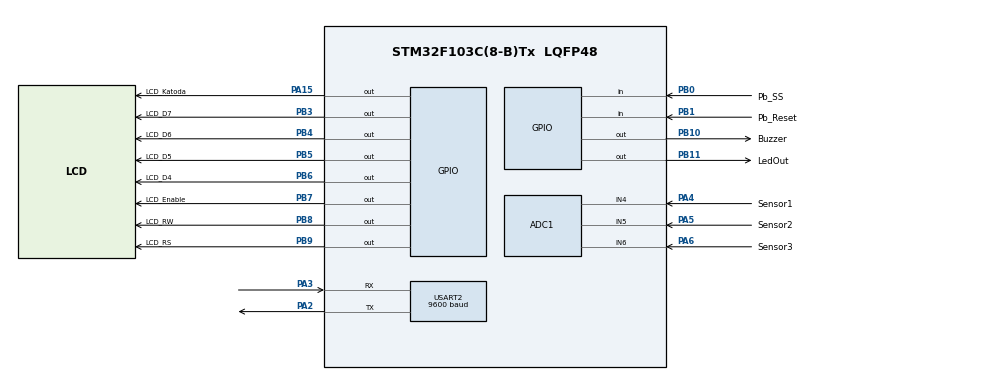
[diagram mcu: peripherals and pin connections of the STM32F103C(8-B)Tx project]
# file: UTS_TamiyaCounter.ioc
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ADC1.Channel-0\#ChannelRegularConversion=ADC_CHANNEL_4
ADC1.Channel-1\#ChannelRegularConversion=ADC_CHANNEL_5
ADC1.Channel-2\#ChannelRegularConversion=ADC_CHANNEL_6
ADC1.Channel-3\#ChannelRegularConversion=ADC_CHANNEL_4
ADC1.ContinuousConvMode=ENABLE
ADC1.NbrOfConversion=4
ADC1.NbrOfConversionFlag=1
ADC1.Rank-0\#ChannelRegularConversion=1
ADC1.Rank-1\#ChannelRegularConversion=2
ADC1.Rank-2\#ChannelRegularConversion=3
ADC1.Rank-3\#ChannelRegularConversion=4
ADC1.SamplingTime-0\#ChannelRegularConversion=ADC_SAMPLETIME_239CYCLES_5
ADC1.SamplingTime-1\#ChannelRegularConversion=ADC_SAMPLETIME_239CYCLES_5
ADC1.SamplingTime-2\#ChannelRegularConversion=ADC_SAMPLETIME_239CYCLES_5
ADC1.SamplingTime-3\#ChannelRegularConversion=ADC_SAMPLETIME_239CYCLES_5
ADC1.master=1
Dma.ADC1.0.Direction=DMA_PERIPH_TO_MEMORY
Dma.ADC1.0.Instance=DMA1_Channel1
Dma.ADC1.0.MemDataAlignment=DMA_MDATAALIGN_WORD
Dma.ADC1.0.MemInc=DMA_MINC_ENABLE
Dma.ADC1.0.Mode=DMA_CIRCULAR
Dma.ADC1.0.PeriphDataAlignment=DMA_PDATAALIGN_WORD
Dma.ADC1.0.PeriphInc=DMA_PINC_DISABLE
Dma.ADC1.0.Priority=DMA_PRIORITY_LOW
Dma.Request0=ADC1
Mcu.Family=STM32F1
Mcu.Name=STM32F103C(8-B)Tx
Mcu.Package=LQFP48
NVIC.ADC1_2_IRQn=true\:0\:0\:false\:false\:true\:true\:true
NVIC.DMA1_Channel1_IRQn=true\:0\:0\:false\:false\:true\:false\:true
NVIC.PriorityGroup=NVIC_PRIORITYGROUP_4
PA13.Mode=Serial_Wire
PA13.Signal=SYS_JTMS-SWDIO
PA14.Mode=Serial_Wire
PA14.Signal=SYS_JTCK-SWCLK
PA15.GPIO_Label=LCD_Katoda
PA15.Signal=GPIO_Output
PA2.Mode=Asynchronous
PA2.Signal=USART2_TX
PA3.Mode=Asynchronous
PA3.Signal=USART2_RX
PA4.GPIO_Label=Sensor1
PA4.Signal=ADCx_IN4
PA5.GPIO_Label=Sensor2
PA5.Signal=ADCx_IN5
PA6.GPIO_Label=Sensor3
PA6.Signal=ADCx_IN6
PB0.GPIO_Label=Pb_SS
PB0.GPIO_PuPd=GPIO_PULLUP
PB0.Signal=GPIO_Input
PB1.GPIO_Label=Pb_Reset
PB1.GPIO_PuPd=GPIO_PULLUP
PB1.Signal=GPIO_Input
PB10.GPIO_Label=Buzzer
PB10.Signal=GPIO_Output
PB11.GPIO_Label=LedOut
PB11.Signal=GPIO_Output
PB3.GPIO_Label=LCD_D7
PB3.Signal=GPIO_Output
PB4.GPIO_Label=LCD_D6
PB4.Signal=GPIO_Output
PB5.GPIO_Label=LCD_D5
PB5.Signal=GPIO_Output
PB6.GPIO_Label=LCD_D4
PB6.Signal=GPIO_Output
PB7.GPIO_Label=LCD_Enable
PB7.Signal=GPIO_Output
PB8.GPIO_Label=LCD_RW
PB8.Signal=GPIO_Output
PB9.GPIO_Label=LCD_RS
PB9.Signal=GPIO_Output
PD0-OSC_IN.Mode=HSE-External-Oscillator
PD0-OSC_IN.Signal=RCC_OSC_IN
PD1-OSC_OUT.Mode=HSE-External-Oscillator
PD1-OSC_OUT.Signal=RCC_OSC_OUT
ProjectManager.HeapSize=0x200
ProjectManager.StackSize=0x400
ProjectManager.TargetToolchain=STM32CubeIDE
RCC.ADCPresc=RCC_ADCPCLK2_DIV6
RCC.AHBFreq_Value=72000000
RCC.APB1CLKDivider=RCC_HCLK_DIV2
RCC.APB1Freq_Value=36000000
RCC.APB1TimFreq_Value=72000000
RCC.APB2Freq_Value=72000000
RCC.APB2TimFreq_Value=72000000
RCC.HCLKFreq_Value=72000000
RCC.PLLMUL=RCC_PLL_MUL9
RCC.PLLSourceVirtual=RCC_PLLSOURCE_HSE
RCC.SYSCLKFreq_VALUE=72000000
RCC.SYSCLKSource=RCC_SYSCLKSOURCE_PLLCLK
RCC.USBFreq_Value=72000000
SH.ADCx_IN4.0=ADC1_IN4,IN4
SH.ADCx_IN5.0=ADC1_IN5,IN5
SH.ADCx_IN6.0=ADC1_IN6,IN6
USART2.BaudRate=9600
USART2.VirtualMode=VM_ASYNC
board=custom

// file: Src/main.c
#include "main.h"

/* USER CODE BEGIN Includes */
#include "stm32f1xx_hal.h"
#include "LCDku.h"
#include "HardwareInitku.h"
#include "SCHtimeku.h"
#include "SCHtimeku2.h"
#include "Sensorku.h"
#include "Taskku.h"
/* USER CODE END Includes */
int main(void)
{
	HAL_Init();
	SystemClock_Config();
	/* Initialize all configured peripherals */
	MX_GPIO_Init();
	MX_DMA_Init();
	MX_ADC1_Init();
	MX_USART2_UART_Init();
	/* USER CODE BEGIN 2 */
	Task_Init();
	Open_ADC_Init();
	LCD_Init();
	HAL_GPIO_WritePin(LCD_Katoda_GPIO_Port, LCD_Katoda_Pin, GPIO_PIN_SET);
	SCH_Init();
	SCH_Init2();
	/* USER CODE END 2 */

	/* Infinite loop */
	while (1)
	{

	}
}

void Error_Handler(void)
{
}

/************************ (C) COPYRIGHT STMicroelectronics *****END OF FILE****/
